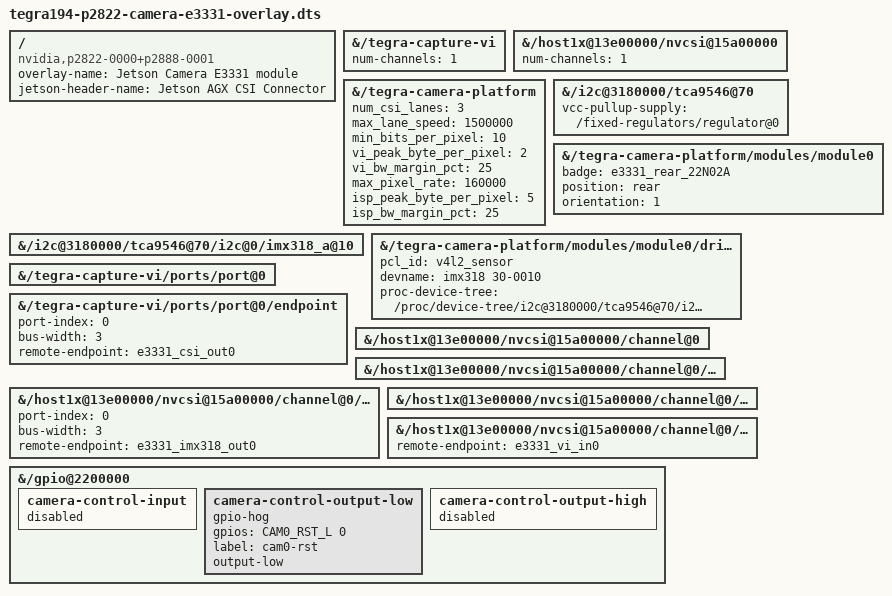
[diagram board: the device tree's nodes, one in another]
// SPDX-License-Identifier: GPL-2.0-only
/*
 * Jetson Device-tree overlay for Camera E3331 on t19x platforms
 *
 * Copyright (c) 2022 NVIDIA CORPORATION. All rights reserved.
 *
 */


/dts-v1/;
/plugin/;

#include <dt-bindings/gpio/tegra194-gpio.h>

#define CAM0_RST_L	TEGRA194_MAIN_GPIO(H, 3)
#define CAM0_PWDN	TEGRA194_MAIN_GPIO(H, 6)
#define CAM1_RST_L	TEGRA194_MAIN_GPIO(T, 6)
#define CAM1_PWDN	TEGRA194_MAIN_GPIO(T, 5)

/ {
	overlay-name = "Jetson Camera E3331 module";
	jetson-header-name = "Jetson AGX CSI Connector";
	compatible = "nvidia,p2822-0000+p2888-0001","nvidia,jetson-xavier-industrial";

	/* E3331 camera board */

	/* VI number of channels */
	fragment@0 {
		/// target = <&capture_vi_base>;
		target-path = "/tegra-capture-vi";
		board_config {
			ids = "3331-*";
			sw-modules = "kernel";
		};
		__overlay__ {
			num-channels=<1>;	 /* TODO change to 3 */
		};
	};
	/* CSI number of channels */
	fragment@1 {
		/// target = <&csi_base>;
		target-path = "/host1x@13e00000/nvcsi@15a00000";
		board_config {
			ids = "3331-*";
			sw-modules = "kernel";
		};
		__overlay__ {
			num-channels=<1>;	/* TODO change to 3 */
		};
	};
	/* tegra-camera-platform settings */
	fragment@2 {
		/// target = <&tcp>;
		target-path = "/tegra-camera-platform";
		board_config {
			ids = "3331-*";
			sw-modules = "kernel";
		};
		__overlay__ {
				num_csi_lanes = <3>;
				max_lane_speed = <1500000>;
				min_bits_per_pixel = <10>;
				vi_peak_byte_per_pixel = <2>;
				vi_bw_margin_pct = <25>;
				max_pixel_rate = <160000>;
				isp_peak_byte_per_pixel = <5>;
				isp_bw_margin_pct = <25>;
		};
	};
	/* TCA9546 */
	fragment@3 {
		/// target = <&tca9546_70>;
		target-path = "/i2c@3180000/tca9546@70";
		board_config {
			ids = "3331-*";
			sw-modules = "kernel";
		};
		__overlay__ {
			status = "okay";
			/// vcc-pullup-supply = <&battery_reg>;
			vcc-pullup-supply = "/fixed-regulators/regulator@0";
		};
	};
	/* Camera 0: Module */
	fragment@4 {
		/// target = <&e3331_cam0>;
		target-path = "/i2c@3180000/tca9546@70/i2c@0/imx318_a@10";
		board_config {
			ids = "3331-*";
			sw-modules = "kernel";
		};
		__overlay__ {
			status = "okay";
		};
	};
	fragment@5 {
		/// target = <&cam_module0>;
		target-path = "/tegra-camera-platform/modules/module0";
		board_config {
			ids = "3331-*";
			sw-modules = "kernel";
		};
		__overlay__ {
			status = "okay";
			badge = "e3331_rear_22N02A";
			position = "rear";
			orientation = "1";
		};
	};
	fragment@6 {
		/// target = <&cam_module0_drivernode0>;
		target-path = "/tegra-camera-platform/modules/module0/drivernode0";
		board_config {
			ids = "3331-*";
			sw-modules = "kernel";
		};
		__overlay__ {
			status = "okay";
			pcl_id = "v4l2_sensor";
			devname = "imx318 30-0010";
			proc-device-tree = "/proc/device-tree/i2c@3180000/tca9546@70/i2c@0/imx318_a@10";
		};
	};
	/* Camera 0: VI */
	fragment@7 {
		/// target = <&vi_port0>;
		target-path = "/tegra-capture-vi/ports/port@0";
		board_config {
			ids = "3331-*";
			sw-modules = "kernel";
		};
		__overlay__ {
			status = "okay";
		};
	};
	fragment@8 {
		/// target = <&e3331_vi_in0>;
		target-path = "/tegra-capture-vi/ports/port@0/endpoint";
		board_config {
			ids = "3331-*";
			sw-modules = "kernel";
		};
		__overlay__ {
			status = "okay";
			port-index = <0>;
			bus-width = <3>;
			remote-endpoint = <&e3331_csi_out0>;
			/// remote-endpoint = "/host1x@13e00000/nvcsi@15a00000/channel@0/ports/port@1/endpoint@1";
		};
	};
	/* Camera 0: CSI */
	fragment@9 {
		/// target = <&csi_chan0>;
		target-path = "/host1x@13e00000/nvcsi@15a00000/channel@0";
		board_config {
			ids = "3331-*";
			sw-modules = "kernel";
		};
		__overlay__ {
			status = "okay";
		};
	};
	fragment@10 {
		/// target = <&csi_chan0_port0>;
		target-path = "/host1x@13e00000/nvcsi@15a00000/channel@0/ports/port@0";
		board_config {
			ids = "3331-*";
			sw-modules = "kernel";
		};
		__overlay__ {
			status = "okay";
		};
	};
	fragment@11 {
		/// target = <&e3331_csi_in0>;
		target-path = "/host1x@13e00000/nvcsi@15a00000/channel@0/ports/port@0/endpoint@0";
		board_config {
			ids = "3331-*";
			sw-modules = "kernel";
		};
		__overlay__ {
			status = "okay";
			port-index = <0>;
			bus-width = <3>;
			remote-endpoint = <&e3331_imx318_out0>;
			/// remote-endpoint = "/i2c@3180000/tca9546@70/i2c@0/imx318_a@10/ports/port@0/endpoint";
		};
	};
	fragment@12 {
		/// target = <&csi_chan0_port1>;
		target-path = "/host1x@13e00000/nvcsi@15a00000/channel@0/ports/port@1";
		board_config {
			ids = "3331-*";
			sw-modules = "kernel";
		};
		__overlay__ {
			status = "okay";
		};
	};
	fragment@13 {
		/// target = <&e3331_csi_out0>;
		target-path = "/host1x@13e00000/nvcsi@15a00000/channel@0/ports/port@1/endpoint@1";
		board_config {
			ids = "3331-*";
			sw-modules = "kernel";
		};
		__overlay__ {
			status = "okay";
			remote-endpoint = <&e3331_vi_in0>;
			/// remote-endpoint = "/tegra-capture-vi/ports/port@0/endpoint";
		};
	};
	/* GPIO */
	fragment@14 {
		/// target = <&{/gpio@2200000}>;
		target-path = "/gpio@2200000";
		board_config {
			ids = "3331-*";
			sw-modules = "kernel";
		};
		__overlay__ {
			camera-control-input {
				status = "disabled";
			};
			camera-control-output-low {
				gpio-hog;
				gpios = <CAM0_RST_L 0>;
				/*<CAM1_RST_L 0> <CAM2_RST_L 0>*/
				label = "cam0-rst";
				/*"cam1-rst", "cam2-rst";*/
				output-low;
				status = "okay";
			};
			camera-control-output-high {
				status = "disabled";
			};
		};
	};
};
